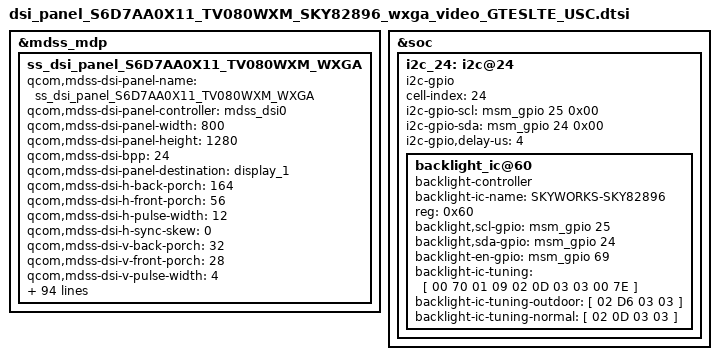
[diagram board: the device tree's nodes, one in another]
/* Copyright (c) 2013, The Linux Foundation. All rights reserved.
 *
 * This program is free software; you can redistribute it and/or modify
 * it under the terms of the GNU General Public License version 2 and
 * only version 2 as published by the Free Software Foundation.
 *
 * This program is distributed in the hope that it will be useful,
 * but WITHOUT ANY WARRANTY; without even the implied warranty of
 * MERCHANTABILITY or FITNESS FOR A PARTICULAR PURPOSE.  See the
 * GNU General Public License for more details.
 */

/*---------------------------------------------------------------------------
 * This file is autogenerated file using gcdb parser. Please do not edit it.
 * Update input XML file to add a new entry or update variable in this file
 * VERSION = "1.0"
 *---------------------------------------------------------------------------*/
&mdss_mdp {
	ss_dsi_panel_S6D7AA0X11_TV080WXM_WXGA: ss_dsi_panel_S6D7AA0X11_TV080WXM_WXGA {
		qcom,mdss-dsi-panel-name = "ss_dsi_panel_S6D7AA0X11_TV080WXM_WXGA";
		qcom,mdss-dsi-panel-controller = <&mdss_dsi0>;
		qcom,mdss-dsi-panel-width = <800>;
		qcom,mdss-dsi-panel-height = <1280>;
		qcom,mdss-dsi-bpp = <24>;
		qcom,mdss-dsi-panel-destination = "display_1";
		qcom,mdss-dsi-h-back-porch = <164>;
		qcom,mdss-dsi-h-front-porch = <56>;
		qcom,mdss-dsi-h-pulse-width = <12>;
		qcom,mdss-dsi-h-sync-skew = <0>;
		qcom,mdss-dsi-v-back-porch = <32>;
		qcom,mdss-dsi-v-front-porch = <28>;
		qcom,mdss-dsi-v-pulse-width = <4>;
		qcom,mdss-dsi-t-clk-pre = <0x1E>;
		qcom,mdss-dsi-t-clk-post = <0x04>;
		/*
			bitclk	520Mhz
			escclk	19.2Mhz
			UI	1.92ns
			Tlpx	52.08333333ns

			T_CLK_PREPARE	70
			T_CLK_ZERO	300
			T_CLK_TRAIL	85
			T_HS_PREPARE	72
			T_HS_ZERO	164
			T_HS_TRAIL	105
			T_HS_RQST	
			T_HS_EXIT	120
			T_TA_GO 312.5
			T_TA_SURE	78.125
			T_TA_GET	390.625
			TEOT	
			T_CLK_POST	164
			T_CLK_PRE	16
		*/
		qcom,mdss-dsi-panel-timings = [
			90 1E 14 00 44 4A 18 26 26 03 04 00
		];

		qcom,mdss-dsi-on-command = [
			39 00 00 00 00 00 03 F0 5A 5A
			39 00 00 00 00 00 03 F1 5A 5A
			39 00 00 00 00 00 03 FC A5 A5

			39 00 00 00 00 00 03 D0 00 10
			39 00 00 00 00 00 04 C3 C7 00 29
			39 00 00 00 00 00 02 B3 51
			39 00 00 00 00 00 02 53 24
			39 00 00 00 00 00 02 51 7F /* PWM DUTY  TEMP CODE*/
			39 00 00 00 00 00 02 C1 01

			/*
				Porch setting 0xF2 register

				HFP 100, HBP 92, HSW 11
				VFP 18, VBP 23, VSW 1
			*/
			39 00 00 00 00 00 06 F2 02 24 1C B0 38

			39 00 00 00 00 00 04 BC 01 4E 0B /* MDNIE RELATED */
			39 00 00 00 00 00 06 FD 16 10 11 23 09 /* MDNIE RELATED */
			39 00 00 00 0A 00 07 FE 00 02 03 21 80 68 /* MDNIE RELATED */

			39 01 00 00 78 00 02 11 00 /* sleep out.  It use last packet*/

			05 01 00 00 00 00 02 29 00  /* DISPLAY ON TEMP CODE */
		];
		qcom,mdss-dsi-off-command = [
			05 01 00 00 24 00 02 28 00			/* wait 40ms(0x24) */
			05 01 00 00 78 00 02 10 00			/* wait 120ms(0x78) */
		];

		qcom,cont-splash-enabled;
		/*qcom,cmd-sync-wait-broadcast = */
		/*qcom,cmd-sync-wait-trigger = */
		/*qcom,mdss-dsi-fbc-enable = */
		/*qcom,mdss-dsi-fbc-slice-height = */
		/*qcom,mdss-dsi-fbc-2d-pred-mode = */
		/*qcom,mdss-dsi-fbc-ver2-mode = */
		/*qcom,mdss-dsi-fbc-bpp = */
		/*qcom,mdss-dsi-fbc-packing = */
		/*qcom,mdss-dsi-fbc-quant-error = */
		/*qcom,mdss-dsi-fbc-bias = */
		/*qcom,mdss-dsi-fbc-pat-mode = */
		/*qcom,mdss-dsi-fbc-vlc-mode = */
		/*qcom,mdss-dsi-fbc-bflc-mode = */
		/*qcom,mdss-dsi-fbc-h-line-budget = */
		/*qcom,mdss-dsi-fbc-budget-ctrl = */
		/*qcom,mdss-dsi-fbc-block-budget = */
		/*qcom,mdss-dsi-fbc-lossless-threshold = */
		/*qcom,mdss-dsi-fbc-lossy-threshold = */
		/*qcom,mdss-dsi-fbc-rgb-threshold = */
		/*qcom,mdss-dsi-fbc-lossy-mode-idx = */
		/*qcom,mdss-dsi-fbc-max-pred-err = */
		qcom,mdss-dsi-h-left-border = <0>;
		qcom,mdss-dsi-h-right-border = <0>;
		qcom,mdss-dsi-v-top-border = <0>;
		qcom,mdss-dsi-v-bottom-border = <0>;
		qcom,mdss-dsi-underflow-color = <0xFF>;
		qcom,mdss-dsi-border-color = <0>;
		/*qcom,mdss-dsi-pan-enable-dynamic-fps = */
		/*qcom,mdss-dsi-pan-fps-update = */
		/*qcom,min-refresh-rate = */
		/*qcom,max-refresh-rate = */
		qcom,mdss-dsi-bl-pmic-control-type = "bl_ctrl_dcs";
		/*qcom,mdss-dsi-bl-pwm-pmi = */
		/*qcom,mdss-dsi-bl-pmic-bank-select = */
		/*qcom,mdss-dsi-bl-pmic-pwm-frequency = */
		/*qcom,mdss-dsi-pwm-gpio = */
		qcom,mdss-dsi-bl-min-level = <1>;
		qcom,mdss-dsi-bl-max-level = <255>;
		qcom,mdss-brightness-max-level = <255>;
		qcom,mdss-dsi-interleave-mode = <0>;
		qcom,mdss-dsi-panel-type = "dsi_video_mode";
		/*qcom,5v-boost-gpio = */
		/*qcom,mdss-dsi-te-check-enable = */
		/*qcom,mdss-dsi-te-using-te-pin = */
		/*qcom,mdss-dsi-te-pin-select = */
		/*qcom,mdss-dsi-te-dcs-command = */
		/*qcom,mdss-dsi-wr-mem-start = */
		/*qcom,mdss-dsi-wr-mem-continue = */
		qcom,mdss-dsi-h-sync-pulse = <0>;
		/*qcom,mdss-dsi-hfp-power-mode = */
		qcom,mdss-dsi-hbp-power-mode;
		/*qcom,mdss-dsi-hsa-power-mode = */
		/*qcom,mdss-dsi-last-line-interleave = */
		qcom,mdss-dsi-bllp-eof-power-mode;
		qcom,mdss-dsi-bllp-power-mode;
		qcom,mdss-dsi-traffic-mode = "burst_mode";
		qcom,mdss-dsi-pixel-packing = "loose";
		qcom,mdss-dsi-virtual-channel-id = <0>;
		qcom,mdss-dsi-color-order = "rgb_swap_rgb";
		qcom,mdss-dsi-lane-0-state;
		qcom,mdss-dsi-lane-1-state;
		qcom,mdss-dsi-lane-2-state;
		qcom,mdss-dsi-lane-3-state;
		qcom,mdss-dsi-lane-map = "lane_map_0123";
		qcom,mdss-dsi-stream = <0>;
		qcom,mdss-dsi-mdp-trigger = "none";
		qcom,mdss-dsi-dma-trigger = "trigger_sw";
		qcom,mdss-dsi-panel-framerate = <60>;
		qcom,mdss-dsi-on-command-state = "dsi_lp_mode";
		qcom,mdss-dsi-off-command-state = "dsi_hs_mode";
		qcom,mdss-dsi-panel-mode-gpio-state = "invalid";
		/*qcom,mdss-tear-check-disable; */
		/*qcom,mdss-tear-check-sync-cfg-height = */
		/*qcom,mdss-tear-check-sync-init-val = */
		/*qcom,mdss-tear-check-sync-threshold-start = */
		/*qcom,mdss-tear-check-sync-threshold-continue = */
		/*qcom,mdss-tear-check-start-pos = */
		/*qcom,mdss-tear-check-rd-ptr-trigger-intr = */
		/*qcom,mdss-tear-check-frame-rate = */
		qcom,mdss-dsi-reset-sequence = <1 20>, <0 20>, <1 20>;
		/*qcom,partial-update-enabled = */
		/*qcom,mdss-dsi-horizontal-line-idle = */
		/*qcom,partial-update-roi-merge = */
		/*qcom,dcs-cmd-by-left = */
		qcom,mdss-dsi-lp11-init;
		qcom,mdss-dsi-init-delay-us = <1000>;
		qcom,mdss-dsi-rx-eot-ignore;
		qcom,mdss-dsi-tx-eot-append;
		/*qcom,ulps-enabled = */
		/*qcom,suspend-ulps-enabled = */
		/*qcom,panel-roi-alignment = */
		qcom,esd-check-enabled;
		/*qcom,mdss-dsi-panel-status-command = */
		/*qcom,mdss-dsi-panel-status-command-mode = */
		qcom,mdss-dsi-panel-status-check-mode="reg_read_irq";
		/*qcom,mdss-dsi-panel-status-read-length = */
		/*qcom,mdss-dsi-panel-status-value = <1>;*/
		/*qcom,mdss-dsi-panel-max-error-count = */
		/*qcom,dynamic-mode-switch-enabled = */
		/*qcom,video-to-cmd-mode-switch-commands = */
		/*qcom,cmd-to-video-mode-switch-commands = */
		/*qcom,mdss-dsi-panel-orientation = */
		/*qcom,panel-ack-disabled = */
		qcom,mdss-dsi-force-clock-lane-hs;
		qcom,mdss-dsi-force-clk-lane-hs = <1>;
		qcom,mdss-pan-physical-width-dimension = <118>;
		qcom,mdss-pan-physical-height-dimension = <171>;
		qcom,esd_irq_gpio = <&msm_gpio 98 0>;
		qcom,mdss-dsi-panel-status-irq-trigger="falling";
/*
 * ************************************************************************************************************************************
 *
 *
 *			Below  parameters are samsung dependent thigs
 *
 *
 * ************************************************************************************************************************************
 */
 		samsung,panel-vendor = "BOE";

		samsung,tft-common-support;

		samsung,esc-clk-128M;

		samsung,display_on_tx_cmds_revA = [05 01 00 00 00 00 02 29 00];

		samsung,level1_key_enable_tx_cmds_revA = [
			29 01 00 00 00 00 03 F0 5A 5A
		];
		samsung,level1_key_disable_tx_cmds_revA = [
			29 01 00 00 00 00 03 F0 A5 A5
		];
		samsung,level2_key_enable_tx_cmds_revA = [
			29 01 00 00 00 00 03 F1 5A 5A
		];
		samsung,level2_key_disable_tx_cmds_revA = [
			29 01 00 00 00 00 03 F1 A5 A5
		];

		samsung,tft_pwm_tx_cmds_revA=[
			39 01 00 00 00 00 02 51 FF /*First command should be PWM duty change command*/
		];
		samsung,cabc_on_tx_cmds_revA = [
			39 01 00 00 00 00 02 55 01
		];
		samsung,cabc_off_tx_cmds_revA = [
			39 01 00 00 00 00 02 55 00
		];
		/*
		 * ************************************************************************************************************************
		 *	 06 01 00 00 00 00 01 c8 07 21
		 *	READ 0xC8 SIZE 0x07 OFFSET 0x21
		 * ************************************************************************************************************************
		 */
		samsung,reg_read_pos_tx_cmds_revA = [ 15 01 00 00 00 00 02 B0 00];
		samsung,packet_size_tx_cmds_revA = [ 37 01 00 00 00 00 02 07 00];

		/* the last byte in all read commands will represent READ LENGH */
		samsung,manufacture_id0_rx_cmds_revA = [ 06 01 00 00 00 00 01 da 01 00];
		samsung,manufacture_id1_rx_cmds_revA = [ 06 01 00 00 00 00 01 db 01 00];
		samsung,manufacture_id2_rx_cmds_revA = [ 06 01 00 00 00 00 01 dc 01 00];

		/*samsung,manufacture_date_rx_cmds_revA = [ 06 01 00 00 00 00 01 C8 02 28];*/
		/*samsung,ddi_id_rx_cmds_revA = [ 06 01 00 00 00 00 01 d6 05 00]; */
		samsung,mtp_read_sysfs_rx_cmds_revA = [ 06 01 00 00 00 00 01 01 01 01];

		samsung,mdnie_read_rx_cmds_revA = [ 06 01 00 00 00 00 01 A1 04 00];

		samsung,ldi_debug0_rx_cmds_revA = [06 01 00 00 00 00 01 0A 01 00];

		/*
		* ************************************************************************************************************************
		* Scaled level to index mappings
		* ************************************************************************************************************************
		*/
		samsung,scaled_level_map_table_revA = <
		/*<idx>	  <from>  <till> <scaled_level> */
			0	0	0	0
			1	1	11	2
			2	12	12	4
			3	13	13	5
			4	14	14	6
			5	15	15	7
			6	16	16	8
			7	17	17	9
			8	18	18	10
			9	19	19	11
			10	20	21	12
			11	22	22	13
			12	23	23	14
			13	24	24	15
			14	25	25	16
			15	26	27	17
			16	28	28	18
			17	29	29	19
			18	30	30	20
			19	31	31	21
			20	32	33	22
			21	34	34	23
			22	35	35	24
			23	36	36	25
			24	37	37	26
			25	38	38	27
			26	39	40	28
			27	41	41	29
			28	42	42	30
			29	43	43	31
			30	44	44	32
			31	45	46	33
			32	47	47	34
			33	48	48	35
			34	49	49	36
			35	50	50	37
			36	51	51	38
			37	52	53	39
			38	54	54	40
			39	55	55	41
			40	56	56	42
			41	57	57	43
			42	58	59	44
			43	60	60	45
			44	61	61	46
			45	62	62	47
			46	63	63	48
			47	64	64	49
			48	65	66	50
			49	67	67	51
			50	68	68	52
			51	69	69	53
			52	70	70	54
			53	71	72	55
			54	73	73	56
			55	74	74	57
			56	75	75	58
			57	76	76	59
			58	77	77	60
			59	78	79	61
			60	80	80	62
			61	81	81	63
			62	82	82	64
			63	83	83	65
			64	84	85	66
			65	86	86	67
			66	87	87	68
			67	88	88	69
			68	89	89	70
			69	90	90	71
			70	91	92	72
			71	93	93	73
			72	94	94	74
			73	95	95	75
			74	96	96	76
			75	97	98	77
			76	99	99	78
			77	100	100	79
			78	101	101	80
			79	102	102	81
			80	103	103	82
			81	104	105	83
			82	106	106	84
			83	107	107	85
			84	108	108	86
			85	109	109	87
			86	110	111	88
			87	112	112	89
			88	113	113	90
			89	114	114	91
			90	115	115	92
			91	116	116	93
			92	117	118	94
			93	119	119	95
			94	120	120	96
			95	121	121	97
			96	122	122	98
			97	123	124	99
			98	125	125	100
			99	126	126	101
			100	127	127	102
			101	128	128	103
			102	129	129	104
			103	130	131	105
			104	132	132	106
			105	133	133	107
			106	134	134	108
			107	135	135	109
			108	136	137	110
			109	138	138	111
			110	139	139	112
			111	140	140	113
			112	141	141	114
			113	142	143	116
			114	144	144	117
			115	145	145	118
			116	146	146	119
			117	147	147	120
			118	148	148	122
			119	149	149	123
			120	150	150	124
			121	151	151	125
			122	152	152	127
			123	153	153	128
			124	154	154	129
			125	155	155	130
			126	156	156	132
			127	157	157	133
			128	158	158	134
			129	159	159	135
			130	160	160	137
			131	161	161	138
			132	162	162	139
			133	163	163	140
			134	164	164	142
			135	165	165	143
			136	166	166	144
			137	167	167	145
			138	168	168	147
			139	169	169	148
			140	170	170	149
			141	171	171	150
			142	172	172	151
			143	173	173	153
			144	174	174	154
			145	175	175	155
			146	176	176	156
			147	177	177	158
			148	178	178	159
			149	179	179	160
			150	180	180	161
			151	181	181	163
			152	182	182	164
			153	183	183	165
			154	184	184	166
			155	185	185	168
			156	186	186	169
			157	187	187	170
			158	188	188	171
			159	189	189	173
			160	190	190	174
			161	191	191	175
			162	192	192	176
			163	193	193	178
			164	194	194	179
			165	195	195	180
			166	196	196	181
			167	197	197	183
			168	198	198	184
			169	199	199	185
			170	200	200	186
			171	201	201	187
			172	202	202	189
			173	203	203	190
			174	204	204	191
			175	205	205	192
			176	206	206	194
			177	207	207	195
			178	208	208	196
			179	209	209	197
			180	210	210	199
			181	211	211	200
			182	212	212	201
			183	213	213	202
			184	214	214	204
			185	215	215	205
			186	216	216	206
			187	217	217	207
			188	218	218	208
			189	219	219	209
			190	220	220	210
			191	221	221	211
			192	222	222	212
			193	223	223	213
			194	224	224	214
			195	225	225	215
			196	226	226	216
			197	227	227	217
			198	228	228	218
			199	229	229	219
			200	230	230	220
			201	231	231	221
			202	232	232	222
			203	233	233	223
			204	234	234	224
			205	235	235	225
			206	236	236	226
			207	237	237	227
			208	238	238	228
			209	239	239	229
			210	240	240	230
			211	241	241	231
			212	242	242	232
			213	243	243	233
			214	244	244	234
			215	245	245	235
			216	246	246	236
			217	247	247	237
			218	248	248	238
			219	249	249	239
			220	250	250	240
			221	251	251	241
			222	252	252	242
			223	253	253	243
			224	254	254	244
			225	255	255	245
		>;
	};
};

&soc {
	i2c_24: i2c@24 {
		cell-index = <24>;
		compatible = "i2c-gpio";
		i2c-gpio-scl = <&msm_gpio 25  0x00>; /*scl gpio*/
		i2c-gpio-sda = <&msm_gpio 24 0x00>;  /*sda gpio*/
		i2c-gpio,delay-us = <4>;

		backlight_ic@60 {
			compatible = "backlight-controller";
			backlight-ic-name = "SKYWORKS-SKY82896";
			reg = <0x60>;
			backlight,scl-gpio = <&msm_gpio 25 0x00>;
			backlight,sda-gpio = <&msm_gpio 24 0x00>;
			backlight-en-gpio = <&msm_gpio 69 0x00>;
			backlight-ic-tuning = [
					00	70
					01	09
					02	0D
					03	03
					00	7E
			];
			backlight-ic-tuning-outdoor = [
					02	D6
					03	03
			];
			backlight-ic-tuning-normal = [
					02	0D
					03	03
			];
		};
	};
};
